AUTOSAR XML (schema 00050)
package /RB/Pt/VehFct/DrvDemDet/ItpPedl/Components
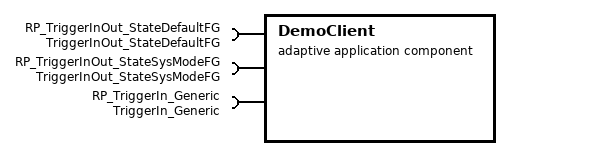
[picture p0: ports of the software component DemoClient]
  adaptive application sw component type DemoClient
    require port RP_TriggerInOut_StateDefaultFG: required-interface=TriggerInOut_StateDefaultFG
    require port RP_TriggerInOut_StateSysModeFG: required-interface=TriggerInOut_StateSysModeFG
    require port RP_TriggerIn_Generic: required-interface=TriggerIn_Generic
